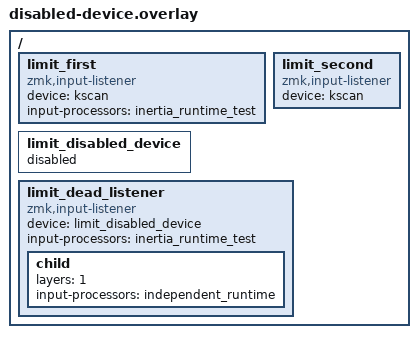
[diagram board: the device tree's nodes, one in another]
/* SPDX-License-Identifier: MIT */
/ {
    limit_first { compatible = "zmk,input-listener"; device = <&kscan>;
        input-processors = <&inertia_runtime_test>;
    };
    limit_second { compatible = "zmk,input-listener"; device = <&kscan>; };
    limit_disabled_device: limit_disabled_device { status = "disabled"; };
    limit_dead_listener { compatible = "zmk,input-listener";
        device = <&limit_disabled_device>;
        input-processors = <&inertia_runtime_test>;
        child { layers = <1>; input-processors = <&independent_runtime>; };
    };
};
